VERSION ""

NS_ :

BS_:

BU_: ACU AMP CGW CLU CTM ESC FCA LDW_LKA MDPS RVM TPMS

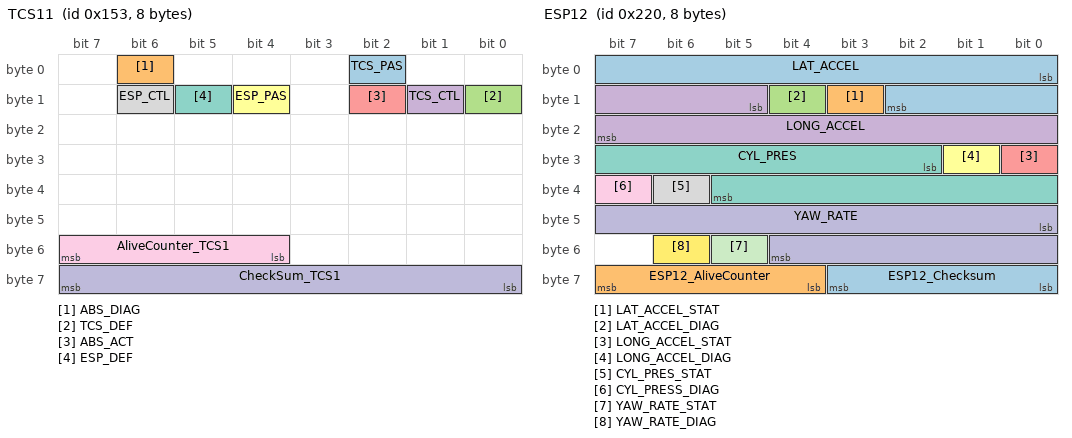
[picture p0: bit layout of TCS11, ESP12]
BO_ 339 TCS11: 8 ESC
 SG_ TCS_PAS : 2|1@1+ (1,0) [0|1] ""  FCA,LDW_LKA
 SG_ ABS_DIAG : 6|1@1+ (1,0) [0|1] ""  FCA,LDW_LKA,MDPS
 SG_ TCS_DEF : 8|1@1+ (1,0) [0|1] ""  FCA,LDW_LKA
 SG_ TCS_CTL : 9|1@1+ (1,0) [0|1] ""  FCA,LDW_LKA,MDPS
 SG_ ABS_ACT : 10|1@1+ (1,0) [0|1] ""  FCA,LDW_LKA
 SG_ ESP_PAS : 12|1@1+ (1,0) [0|1] ""  FCA,LDW_LKA
 SG_ ESP_DEF : 13|1@1+ (1,0) [0|1] ""  FCA,LDW_LKA
 SG_ ESP_CTL : 14|1@1+ (1,0) [0|1] ""  FCA,LDW_LKA,MDPS
 SG_ AliveCounter_TCS1 : 52|4@1+ (1,0) [0|14] ""  FCA
 SG_ CheckSum_TCS1 : 56|8@1+ (1,0) [0|255] ""  FCA

BO_ 356 VSM11_FS: 4 ESC
 SG_ CF_Esc_Act : 12|1@1+ (1,0) [0|1] ""  LDW_LKA,MDPS
 SG_ CRC : 24|8@1+ (1,0) [0|0] ""  LDW_LKA,MDPS

BO_ 544 ESP12: 8 ESC
 SG_ LAT_ACCEL : 0|11@1+ (0.01,-10.23) [-10.23|10.24] "m/s^2"  CLU,FCA,LDW_LKA,MDPS
 SG_ LAT_ACCEL_STAT : 11|1@1+ (1,0) [0|1] ""  CLU,FCA,LDW_LKA,MDPS
 SG_ LAT_ACCEL_DIAG : 12|1@1+ (1,0) [0|1] ""  FCA,LDW_LKA
 SG_ LONG_ACCEL : 13|11@1+ (0.01,-10.23) [-10.23|10.24] "m/s^2"  CLU,FCA,LDW_LKA
 SG_ LONG_ACCEL_STAT : 24|1@1+ (1,0) [0|1] ""  CLU,FCA,LDW_LKA
 SG_ LONG_ACCEL_DIAG : 25|1@1+ (1,0) [0|1] ""  FCA,LDW_LKA
 SG_ CYL_PRES : 26|12@1+ (0.1,0) [0|409.5] "Bar"  FCA,LDW_LKA
 SG_ CYL_PRES_STAT : 38|1@1+ (1,0) [0|1] ""  CGW,FCA,LDW_LKA
 SG_ CYL_PRESS_DIAG : 39|1@1+ (1,0) [0|1] ""  FCA,LDW_LKA
 SG_ YAW_RATE : 40|13@1+ (0.01,-40.95) [-40.95|40.96] "˚/s"  FCA,LDW_LKA,MDPS
 SG_ YAW_RATE_STAT : 53|1@1+ (1,0) [0|1] ""  FCA,LDW_LKA,MDPS
 SG_ YAW_RATE_DIAG : 54|1@1+ (1,0) [0|1] ""  FCA,LDW_LKA
 SG_ ESP12_Checksum : 56|4@1+ (1,0) [0|15] ""  FCA,LDW_LKA
 SG_ ESP12_AliveCounter : 60|4@1+ (1,0) [0|15] ""  FCA,LDW_LKA

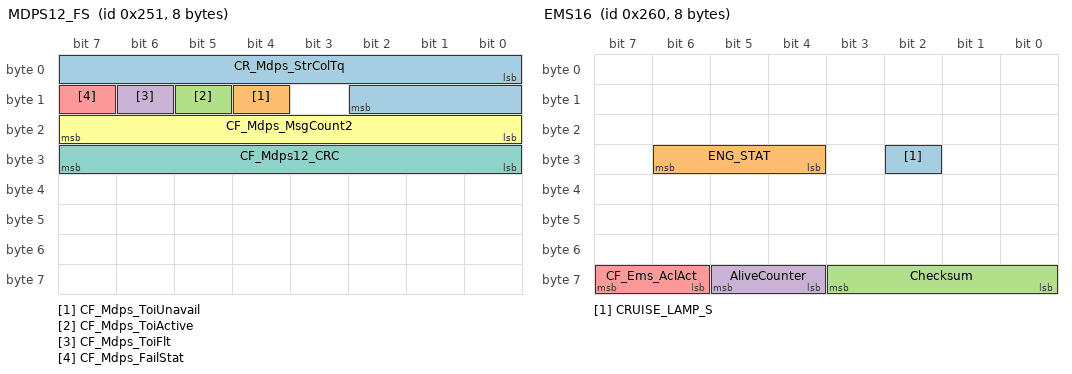
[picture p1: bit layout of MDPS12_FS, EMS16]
BO_ 593 MDPS12_FS: 8 MDPS
 SG_ CR_Mdps_StrColTq : 0|11@1+ (0.0078125,-8) [-8|7.984375] "Nm"  CGW,LDW_LKA
 SG_ CF_Mdps_ToiUnavail : 12|1@1+ (1,0) [0|1] ""  LDW_LKA
 SG_ CF_Mdps_ToiActive : 13|1@1+ (1,0) [0|1] ""  LDW_LKA
 SG_ CF_Mdps_ToiFlt : 14|1@1+ (1,0) [0|1] ""  LDW_LKA
 SG_ CF_Mdps_FailStat : 15|1@1+ (1,0) [0|1] ""  LDW_LKA
 SG_ CF_Mdps_MsgCount2 : 16|8@1+ (1,0) [0|255] ""  ESC,LDW_LKA
 SG_ CF_Mdps12_CRC : 24|8@1+ (1,0) [0|0] ""  CGW,ESC,LDW_LKA

BO_ 608 EMS16: 8 CGW
 SG_ CRUISE_LAMP_S : 26|1@1+ (1,0) [0|1] ""  CLU,LDW_LKA
 SG_ ENG_STAT : 28|3@1+ (1,0) [0|7] ""  CLU,CTM,FCA,LDW_LKA,MDPS,RVM
 SG_ Checksum : 56|4@1+ (1,0) [0|15] ""  FCA,MDPS
 SG_ AliveCounter : 60|2@1+ (1,0) [0|3] ""  FCA,MDPS
 SG_ CF_Ems_AclAct : 62|2@1+ (1,0) [0|3] ""  FCA

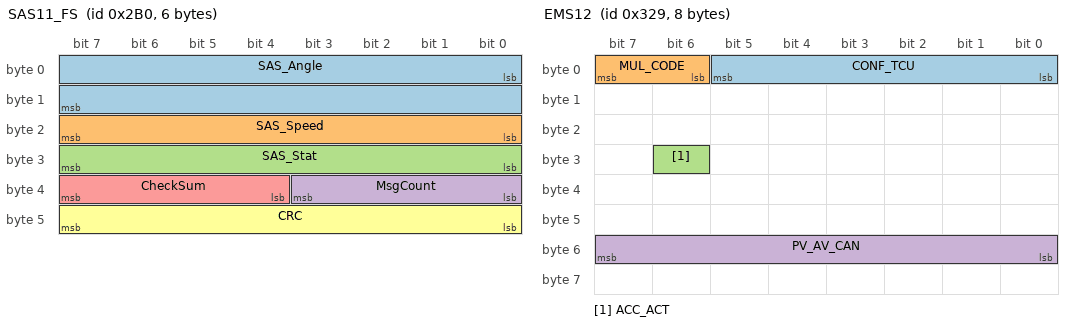
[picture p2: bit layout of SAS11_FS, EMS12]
BO_ 688 SAS11_FS: 6 MDPS
 SG_ SAS_Angle : 0|16@1- (0.1,0) [-3276.8|3276.7] "Deg"  CGW,CLU,ESC,FCA,LDW_LKA,RVM
 SG_ SAS_Speed : 16|8@1+ (4,0) [0|1016] ""  CGW,ESC,FCA,LDW_LKA
 SG_ SAS_Stat : 24|8@1+ (1,0) [0|255] ""  CGW,ESC,FCA,LDW_LKA
 SG_ MsgCount : 32|4@1+ (1,0) [0|15] ""  CGW,ESC,FCA,LDW_LKA
 SG_ CheckSum : 36|4@1+ (1,0) [0|15] ""  CGW,ESC,FCA,LDW_LKA
 SG_ CRC : 40|8@1+ (1,0) [0|0] ""  ESC,FCA,LDW_LKA

BO_ 809 EMS12: 8 CGW
 SG_ CONF_TCU : 0|6@1+ (1,0) [0|63] ""  CLU,FCA,LDW_LKA
 SG_ MUL_CODE : 6|2@1+ (1,0) [0|3] ""  CLU,FCA,LDW_LKA
 SG_ ACC_ACT : 30|1@1+ (1,0) [0|1] ""  AMP,FCA
 SG_ PV_AV_CAN : 48|8@1+ (0.3906,0) [0|99.603] "%"  FCA,LDW_LKA,MDPS

BO_ 832 LKA11_FS: 8 LDW_LKA
 SG_ CF_LKA_LaneRecogState : 0|2@1+ (1,0) [0|3] ""  CGW,CLU
 SG_ CF_LKA_SysWarning : 6|4@1+ (1,0) [0|15] ""  CLU
 SG_ CF_LKA_LHWarning : 10|2@1+ (1,0) [0|3] ""  CLU
 SG_ CF_LKA_RHWarning : 12|2@1+ (1,0) [0|3] ""  CLU
 SG_ CF_HBA_Lamp : 14|1@1+ (1,0) [0|1] ""  CLU
 SG_ CF_LKA_HandsOff_Snd : 15|1@1+ (1,0) [0|1] ""  CLU
 SG_ CR_LKA_StrToqReq : 16|11@1+ (0.0078125,-8) [-8|8] "Nm"  MDPS
 SG_ CF_LKA_ActToi : 27|1@1+ (1,0) [0|1] ""  MDPS
 SG_ CF_LKA_ToiFlt : 28|1@1+ (1,0) [0|1] ""  MDPS
 SG_ CF_HBA_SysState : 29|3@1+ (1,0) [0|7] ""  CGW,CLU
 SG_ CF_HBA_Opt_USM : 32|2@1+ (1,0) [0|3] ""  CGW,CLU
 SG_ CF_HBA_Opt : 34|1@1+ (1,0) [0|1] ""  CGW,CLU
 SG_ CF_LKA_MsgCount : 36|4@1+ (1,0) [0|15] ""  CLU,MDPS
 SG_ CF_LKA_FusionState : 45|2@1+ (1,0) [0|3] ""  Vector__XXX
 SG_ CF_LKA_CRC : 48|8@1+ (1,0) [0|255] ""  MDPS
 SG_ CF_LKA_SymbolState : 56|3@1+ (1,0) [0|7] ""  CLU
 SG_ CF_HBA_Lamp_New : 62|2@1+ (1,0) [0|1] ""  CLU

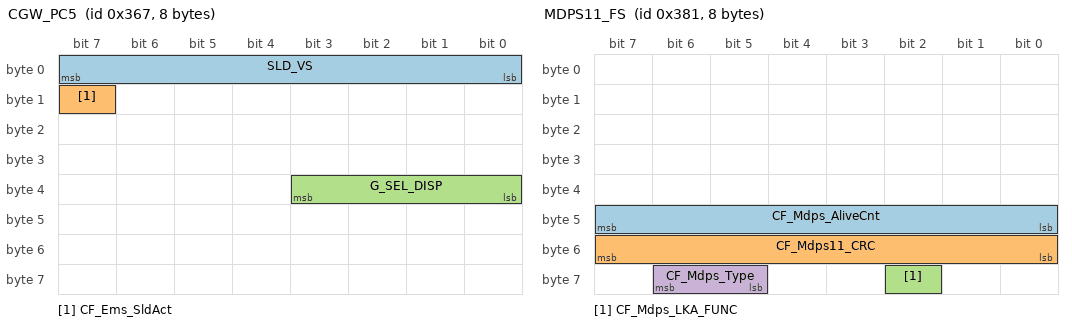
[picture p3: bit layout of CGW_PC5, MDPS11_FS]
BO_ 871 CGW_PC5: 8 CGW
 SG_ SLD_VS : 0|8@1+ (1,0) [0|255] "km/h"  CLU,LDW_LKA
 SG_ CF_Ems_SldAct : 15|1@1+ (1,0) [0|1] ""  CLU,LDW_LKA
 SG_ G_SEL_DISP : 32|4@1+ (1,0) [0|15] ""  CLU,FCA,LDW_LKA,MDPS,RVM

BO_ 897 MDPS11_FS: 8 MDPS
 SG_ CF_Mdps_AliveCnt : 40|8@1+ (1,0) [0|255] ""  LDW_LKA
 SG_ CF_Mdps11_CRC : 48|8@1+ (1,0) [0|0] ""  CGW,LDW_LKA
 SG_ CF_Mdps_LKA_FUNC : 58|1@1+ (1,0) [0|1] "flag"  LDW_LKA
 SG_ CF_Mdps_Type : 61|2@1+ (1,0) [0|2] ""  ESC,LDW_LKA

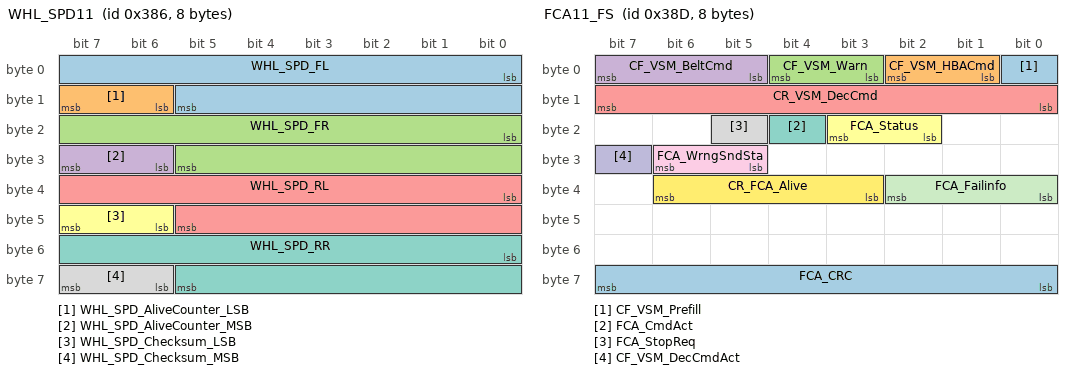
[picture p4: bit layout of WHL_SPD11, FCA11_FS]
BO_ 902 WHL_SPD11: 8 CGW
 SG_ WHL_SPD_FL : 0|14@1+ (0.03125,0) [0|511.96875] "km/h"  CLU,FCA,LDW_LKA,MDPS,RVM
 SG_ WHL_SPD_AliveCounter_LSB : 14|2@1+ (1,0) [0|3] ""  FCA,LDW_LKA
 SG_ WHL_SPD_FR : 16|14@1+ (0.03125,0) [0|511.96875] "km/h"  CLU,FCA,LDW_LKA,MDPS,RVM
 SG_ WHL_SPD_AliveCounter_MSB : 30|2@1+ (1,0) [0|3] ""  FCA,LDW_LKA
 SG_ WHL_SPD_RL : 32|14@1+ (0.03125,0) [0|511.96875] "km/h"  CLU,FCA,LDW_LKA,MDPS,RVM
 SG_ WHL_SPD_Checksum_LSB : 46|2@1+ (1,0) [0|3] ""  FCA,LDW_LKA
 SG_ WHL_SPD_RR : 48|14@1+ (0.03125,0) [0|511.96875] "km/h"  CLU,FCA,LDW_LKA,MDPS,RVM
 SG_ WHL_SPD_Checksum_MSB : 62|2@1+ (1,0) [0|3] ""  FCA,LDW_LKA

BO_ 909 FCA11_FS: 8 FCA
 SG_ CF_VSM_Prefill : 0|1@1+ (1,0) [0|1] ""  ESC
 SG_ CF_VSM_HBACmd : 1|2@1+ (1,0) [0|3] ""  ESC
 SG_ CF_VSM_Warn : 3|2@1+ (1,0) [0|3] ""  ACU,CGW,CLU,ESC
 SG_ CF_VSM_BeltCmd : 5|3@1+ (1,0) [0|7] ""  Vector__XXX
 SG_ CR_VSM_DecCmd : 8|8@1+ (0.01,0) [0|2.55] "g"  ESC
 SG_ FCA_Status : 18|2@1+ (1,0) [0|3] ""  ACU,CLU,ESC
 SG_ FCA_CmdAct : 20|1@1+ (1,0) [0|1] ""  ESC
 SG_ FCA_StopReq : 21|1@1+ (1,0) [0|1] ""  CLU,ESC
 SG_ FCA_WrngSndSta : 29|2@1+ (1,0) [0|3] ""  CLU
 SG_ CF_VSM_DecCmdAct : 31|1@1+ (1,0) [0|1] ""  ESC
 SG_ FCA_Failinfo : 32|3@1+ (1,0) [0|7] ""  ACU,CLU,ESC
 SG_ CR_FCA_Alive : 35|4@1+ (1,0) [0|15] ""  ESC
 SG_ FCA_CRC : 56|8@1+ (1,0) [0|0] ""  ESC

BO_ 913 CLU21: 8 CLU
 SG_ CF_Clu_LFASwState : 4|1@1+ (1,0) [0|1] ""  LDW_LKA

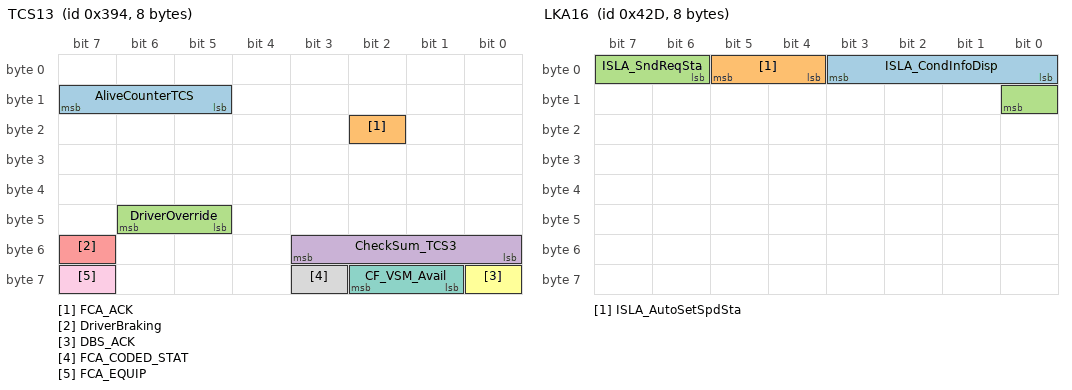
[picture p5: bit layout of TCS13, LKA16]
BO_ 916 TCS13: 8 ESC
 SG_ AliveCounterTCS : 13|3@1+ (1,0) [0|7] ""  CGW,FCA
 SG_ FCA_ACK : 18|1@1+ (1,0) [0|1] ""  FCA
 SG_ DriverOverride : 45|2@1+ (1,0) [0|3] ""  CGW,FCA,LDW_LKA
 SG_ CheckSum_TCS3 : 48|4@1+ (1,0) [0|15] ""  CGW,FCA
 SG_ DriverBraking : 55|1@1+ (1,0) [0|1] ""  CGW,FCA,LDW_LKA
 SG_ DBS_ACK : 56|1@1+ (1,0) [0|1] ""  FCA
 SG_ CF_VSM_Avail : 57|2@1+ (1,0) [0|3] ""  CGW,FCA,LDW_LKA
 SG_ FCA_CODED_STAT : 59|1@1+ (1,0) [0|0] ""  FCA
 SG_ FCA_EQUIP : 63|1@1+ (1,0) [0|1] ""  FCA

BO_ 1069 LKA16: 8 LDW_LKA
 SG_ ISLA_CondInfoDisp : 0|4@1+ (1,0) [0|0] ""  CGW,CLU
 SG_ ISLA_AutoSetSpdSta : 4|2@1+ (1,0) [0|0] ""  CLU
 SG_ ISLA_SndReqSta : 6|3@1+ (1,0) [0|0] ""  CLU

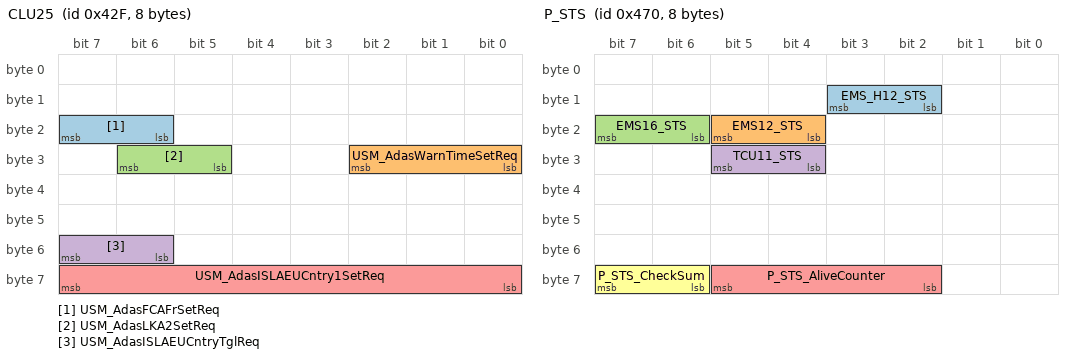
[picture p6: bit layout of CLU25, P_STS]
BO_ 1071 CLU25: 8 CLU
 SG_ USM_AdasFCAFrSetReq : 22|2@1+ (1,0) [0|3] ""  FCA
 SG_ USM_AdasWarnTimeSetReq : 24|3@1+ (1,0) [0|7] ""  FCA,LDW_LKA
 SG_ USM_AdasLKA2SetReq : 29|2@1+ (1,0) [0|3] ""  LDW_LKA
 SG_ USM_AdasISLAEUCntryTglReq : 54|2@1+ (1,0) [0|0] ""  LDW_LKA
 SG_ USM_AdasISLAEUCntry1SetReq : 56|8@1+ (1,0) [0|0] ""  LDW_LKA

BO_ 1107 CGW_PC1: 5 CGW
 SG_ ENG_SldSwSta : 28|2@1+ (1,0) [0|0] ""  CLU,LDW_LKA

BO_ 1136 P_STS: 8 CGW
 SG_ EMS_H12_STS : 10|2@1+ (1,0) [0|3] ""  FCA,LDW_LKA,MDPS
 SG_ EMS12_STS : 20|2@1+ (1,0) [0|3] ""  FCA,LDW_LKA
 SG_ EMS16_STS : 22|2@1+ (1,0) [0|3] ""  FCA,LDW_LKA,MDPS
 SG_ TCU11_STS : 28|2@1+ (1,0) [0|3] ""  FCA,LDW_LKA
 SG_ P_STS_AliveCounter : 58|4@1+ (1,0) [0|15] ""  FCA,LDW_LKA,MDPS
 SG_ P_STS_CheckSum : 62|2@1+ (1,0) [0|3] ""  FCA,LDW_LKA,MDPS

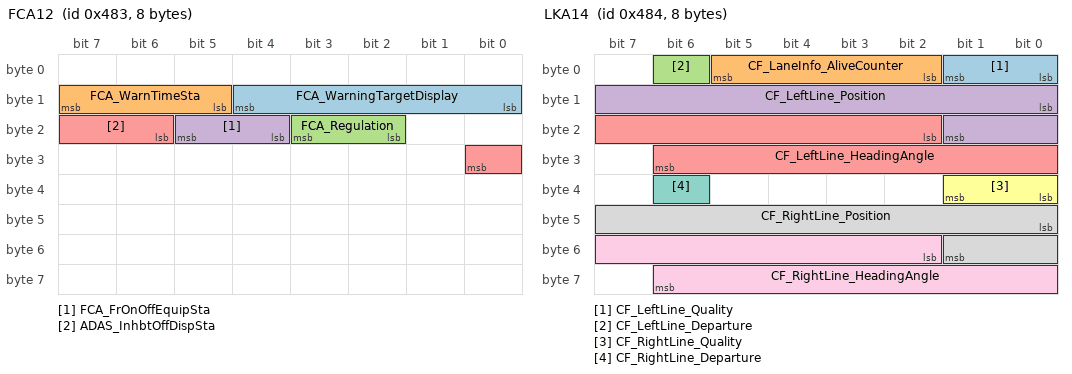
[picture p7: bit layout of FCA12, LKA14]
BO_ 1155 FCA12: 8 FCA
 SG_ FCA_WarningTargetDisplay : 8|5@1+ (1,0) [0|31] ""  CLU
 SG_ FCA_WarnTimeSta : 13|3@1+ (1,0) [0|0] ""  CGW,CLU
 SG_ FCA_Regulation : 18|2@1+ (1,0) [0|0] ""  CLU
 SG_ FCA_FrOnOffEquipSta : 20|2@1+ (1,0) [0|0] ""  CGW,CLU
 SG_ ADAS_InhbtOffDispSta : 22|3@1+ (1,0) [0|0] ""  CLU

BO_ 1156 LKA14: 8 LDW_LKA
 SG_ CF_LeftLine_Quality : 0|2@1+ (1,0) [0|0] ""  Vector__XXX
 SG_ CF_LaneInfo_AliveCounter : 2|4@1+ (1,0) [0|15] ""  Vector__XXX
 SG_ CF_LeftLine_Departure : 6|1@1+ (1,0) [0|1] ""  Vector__XXX
 SG_ CF_LeftLine_Position : 8|10@1- (0.00390625,0) [-2|1.99] ""  Vector__XXX
 SG_ CF_LeftLine_HeadingAngle : 18|13@1+ (0.0000152588,-0.0625) [-0.06|0.06] ""  Vector__XXX
 SG_ CF_RightLine_Quality : 32|2@1+ (1,0) [0|3] ""  Vector__XXX
 SG_ CF_RightLine_Departure : 38|1@1+ (1,0) [0|1] ""  Vector__XXX
 SG_ CF_RightLine_Position : 40|10@1- (0.00390625,0) [-2|1.99] "m"  Vector__XXX
 SG_ CF_RightLine_HeadingAngle : 50|13@1+ (0.0000152588,-0.0625) [-0.06|0.06] ""  Vector__XXX

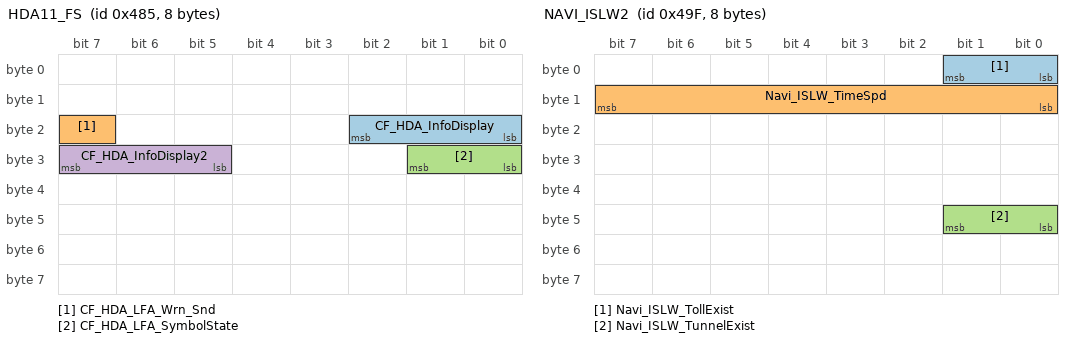
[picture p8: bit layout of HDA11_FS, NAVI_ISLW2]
BO_ 1157 HDA11_FS: 8 LDW_LKA
 SG_ CF_HDA_InfoDisplay : 16|3@1+ (1,0) [0|7] ""  CLU
 SG_ CF_HDA_LFA_Wrn_Snd : 23|1@1+ (1,0) [0|1] ""  CLU
 SG_ CF_HDA_LFA_SymbolState : 24|2@1+ (1,0) [0|3] ""  CGW,CLU
 SG_ CF_HDA_InfoDisplay2 : 29|3@1+ (1,0) [0|7] ""  CLU

BO_ 1183 NAVI_ISLW2: 8 CGW
 SG_ Navi_ISLW_TollExist : 0|2@1+ (1,0) [0|3] ""  LDW_LKA
 SG_ Navi_ISLW_TimeSpd : 8|8@1+ (1,0) [0|254] ""  LDW_LKA
 SG_ Navi_ISLW_TunnelExist : 40|2@1+ (1,0) [0|3] ""  LDW_LKA

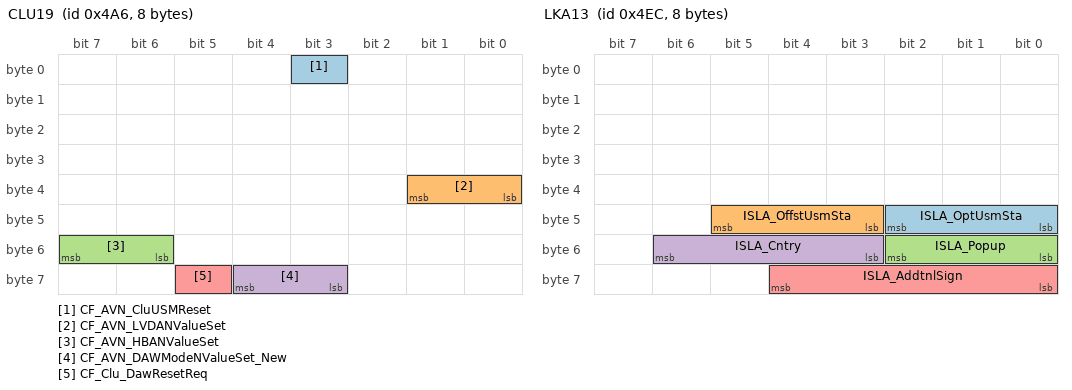
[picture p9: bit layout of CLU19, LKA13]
BO_ 1190 CLU19: 8 CLU
 SG_ CF_AVN_CluUSMReset : 3|1@1+ (1,0) [0|1] ""  FCA,LDW_LKA,RVM
 SG_ CF_AVN_LVDANValueSet : 32|2@1+ (1,0) [0|3] ""  LDW_LKA
 SG_ CF_AVN_HBANValueSet : 54|2@1+ (1,0) [0|3] ""  LDW_LKA
 SG_ CF_AVN_DAWModeNValueSet_New : 59|2@1+ (1,0) [0|3] ""  LDW_LKA
 SG_ CF_Clu_DawResetReq : 61|1@1+ (1,0) [0|1] ""  LDW_LKA

BO_ 1191 LKA15: 2 LDW_LKA
 SG_ CF_FCA_Equip_MFC : 0|3@1+ (1,0) [0|7] ""  ESC,FCA

BO_ 1193 CGW8: 8 CGW
 SG_ C_SMKTeleEngineRunning : 3|1@1+ (1,0) [0|1] ""  LDW_LKA

BO_ 1260 LKA13: 8 LDW_LKA
 SG_ ISLA_OptUsmSta : 40|3@1+ (1,0) [0|0] ""  CGW,CLU
 SG_ ISLA_OffstUsmSta : 43|3@1+ (1,0) [0|0] ""  CGW,CLU
 SG_ ISLA_Popup : 48|3@1+ (1,0) [0|0] ""  CGW,CLU
 SG_ ISLA_Cntry : 51|4@1+ (1,0) [0|0] ""  CGW,CLU
 SG_ ISLA_AddtnlSign : 56|5@1+ (1,0) [0|0] ""  CGW,CLU

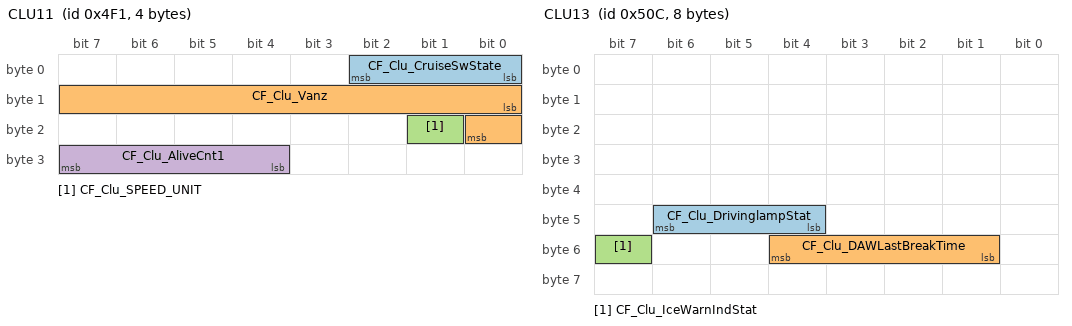
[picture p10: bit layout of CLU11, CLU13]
BO_ 1265 CLU11: 4 CLU
 SG_ CF_Clu_CruiseSwState : 0|3@1+ (1,0) [0|7] ""  CGW,LDW_LKA
 SG_ CF_Clu_Vanz : 8|9@1+ (0.5,0) [0|255.5] "km/h or MPH"  CGW,FCA,LDW_LKA,MDPS,RVM
 SG_ CF_Clu_SPEED_UNIT : 17|1@1+ (1,0) [0|1] ""  ACU,CGW,FCA,LDW_LKA,MDPS,RVM
 SG_ CF_Clu_AliveCnt1 : 28|4@1+ (1,0) [0|15] ""  CGW,FCA,LDW_LKA

BO_ 1292 CLU13: 8 CLU
 SG_ CF_Clu_DrivinglampStat : 44|3@1+ (1,0) [0|7] ""  CGW,ESC,LDW_LKA
 SG_ CF_Clu_DAWLastBreakTime : 49|4@1+ (1,0) [0|15] ""  CGW,LDW_LKA
 SG_ CF_Clu_IceWarnIndStat : 55|1@1+ (1,0) [0|1] ""  LDW_LKA

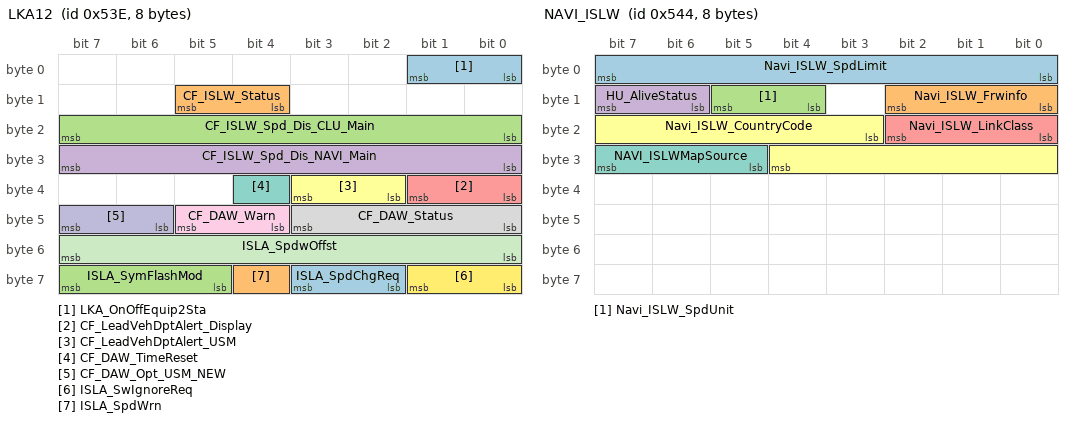
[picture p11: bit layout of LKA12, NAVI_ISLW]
BO_ 1342 LKA12: 8 LDW_LKA
 SG_ LKA_OnOffEquip2Sta : 0|2@1+ (1,0) [0|3] ""  CGW,CLU
 SG_ CF_ISLW_Status : 12|2@1+ (1,0) [0|3] ""  CLU
 SG_ CF_ISLW_Spd_Dis_CLU_Main : 16|8@1+ (1,0) [0|255] ""  CLU
 SG_ CF_ISLW_Spd_Dis_NAVI_Main : 24|8@1+ (1,0) [0|255] ""  CLU
 SG_ CF_LeadVehDptAlert_Display : 32|2@1+ (1,0) [0|3] ""  CLU
 SG_ CF_LeadVehDptAlert_USM : 34|2@1+ (1,0) [0|3] ""  CGW,CLU
 SG_ CF_DAW_TimeReset : 36|1@1+ (1,0) [0|1] ""  CLU
 SG_ CF_DAW_Status : 40|4@1+ (1,0) [0|15] ""  CLU
 SG_ CF_DAW_Warn : 44|2@1+ (1,0) [0|3] ""  CGW,CLU
 SG_ CF_DAW_Opt_USM_NEW : 46|2@1+ (1,0) [0|3] ""  CGW,CLU
 SG_ ISLA_SpdwOffst : 48|8@1+ (1,0) [0|0] ""  CLU
 SG_ ISLA_SwIgnoreReq : 56|2@1+ (1,0) [0|0] ""  CLU
 SG_ ISLA_SpdChgReq : 58|2@1+ (1,0) [0|0] ""  CLU
 SG_ ISLA_SpdWrn : 60|1@1+ (1,0) [0|0] ""  CGW,CLU
 SG_ ISLA_SymFlashMod : 61|3@1+ (1,0) [0|0] ""  CGW,CLU

BO_ 1345 CGW1: 8 CGW
 SG_ CF_Gway_DrvDrSw : 8|2@1+ (1,0) [0|3] ""  CLU,FCA,LDW_LKA
 SG_ CF_Gway_DrvSeatBeltSw : 10|2@1+ (1,0) [0|3] ""  LDW_LKA
 SG_ CF_Gway_TurnSigLh : 19|2@1+ (1,0) [0|3] ""  CLU,CTM,FCA,LDW_LKA
 SG_ CF_Gway_WiperIntT : 21|3@1+ (1,0) [0|7] ""  CLU,LDW_LKA
 SG_ CF_Gway_WiperIntSw : 24|1@1+ (1,0) [0|1] ""  LDW_LKA
 SG_ CF_Gway_WiperLowSw : 25|1@1+ (1,0) [0|1] ""  LDW_LKA
 SG_ CF_Gway_WiperHighSw : 26|1@1+ (1,0) [0|1] ""  LDW_LKA
 SG_ CF_Gway_WiperAutoSw : 27|1@1+ (1,0) [0|1] ""  LDW_LKA
 SG_ CF_Gway_RainSnsState : 28|3@1+ (1,0) [0|7] ""  LDW_LKA
 SG_ CF_Gway_HeadLampHigh : 32|1@1+ (1,0) [0|1] ""  CLU,LDW_LKA
 SG_ CF_Gway_HazardSw : 33|2@1+ (1,0) [0|3] ""  LDW_LKA
 SG_ CF_Gway_AstDrSw : 35|1@1+ (1,0) [0|1] ""  CLU,LDW_LKA
 SG_ CF_Gway_TSigRHSw : 41|1@1+ (1,0) [0|1] ""  LDW_LKA
 SG_ CF_Gway_TSigLHSw : 42|1@1+ (1,0) [0|1] ""  LDW_LKA
 SG_ CF_Gway_HBAControlMode : 52|1@1+ (1,0) [0|1] ""  LDW_LKA
 SG_ CF_Gway_InhibitRMT : 54|2@1+ (1,0) [0|3] ""  CLU,FCA,LDW_LKA,RVM
 SG_ CF_Gway_TurnSigRh : 62|2@1+ (1,0) [0|3] ""  CLU,CTM,FCA,LDW_LKA

BO_ 1348 NAVI_ISLW: 8 CGW
 SG_ Navi_ISLW_SpdLimit : 0|8@1+ (1,0) [1|254] ""  LDW_LKA
 SG_ Navi_ISLW_Frwinfo : 8|3@1+ (1,0) [0|7] ""  LDW_LKA
 SG_ Navi_ISLW_SpdUnit : 12|2@1+ (1,0) [0|3] ""  LDW_LKA
 SG_ HU_AliveStatus : 14|2@1+ (1,0) [0|3] ""  LDW_LKA
 SG_ Navi_ISLW_LinkClass : 16|3@1+ (1,0) [0|7] ""  LDW_LKA
 SG_ Navi_ISLW_CountryCode : 19|10@1+ (1,0) [0|1023] ""  LDW_LKA
 SG_ NAVI_ISLWMapSource : 29|3@1+ (1,0) [0|7] ""  LDW_LKA

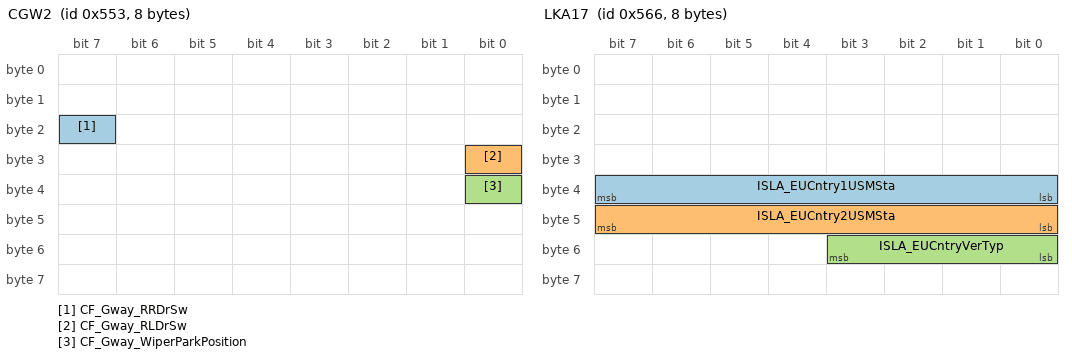
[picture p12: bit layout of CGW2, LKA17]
BO_ 1363 CGW2: 8 CGW
 SG_ CF_Gway_RRDrSw : 23|1@1+ (1,0) [0|1] ""  CLU,LDW_LKA
 SG_ CF_Gway_RLDrSw : 24|1@1+ (1,0) [0|1] ""  CLU,LDW_LKA
 SG_ CF_Gway_WiperParkPosition : 32|1@1+ (1,0) [0|1] ""  LDW_LKA

BO_ 1382 LKA17: 8 LDW_LKA
 SG_ ISLA_EUCntry1USMSta : 32|8@1+ (1,0) [0|0] ""  CGW,CLU
 SG_ ISLA_EUCntry2USMSta : 40|8@1+ (1,0) [0|0] ""  CGW,CLU
 SG_ ISLA_EUCntryVerTyp : 48|4@1+ (1,0) [0|0] ""  CGW,CLU

BO_ 1407 HU_MON_PE_01: 8 CGW
 SG_ HU_Type : 0|8@1+ (1,0) [0|255] ""  LDW_LKA,RVM
 SG_ HU_OptionInfo : 40|16@1+ (1,0) [0|0] ""  FCA

BO_ 1456 CLU12: 4 CLU
 SG_ CF_Clu_Odometer : 0|24@1+ (0.1,0) [0|1677721.4] "km"  CGW,FCA,TPMS

BO_ 1470 HU_CLU_PE_05: 8 CGW
 SG_ HU_NaviStatus : 2|2@1+ (1,0) [0|3] ""  LDW_LKA

BO_ 1474 CLU22: 8 CLU
 SG_ CF_Clu_AdasISLASetReq : 22|3@1+ (1,0) [0|0] ""  LDW_LKA
 SG_ CF_Clu_ISLAOffsetSetReq : 27|3@1+ (1,0) [0|0] ""  LDW_LKA

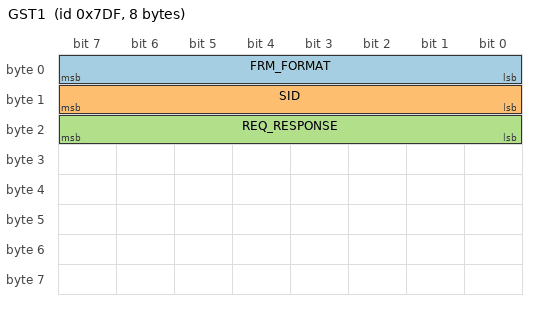
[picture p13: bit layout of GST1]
BO_ 2015 GST1: 8 CGW
 SG_ FRM_FORMAT : 0|8@1+ (1,0) [0|31] ""  CTM,LDW_LKA,MDPS
 SG_ SID : 8|8@1+ (1,0) [0|255] ""  CTM,LDW_LKA,MDPS
 SG_ REQ_RESPONSE : 16|8@1+ (1,0) [0|2] ""  CTM,LDW_LKA,MDPS

CM_ BO_ 339 "[P] Periodic";
CM_ BO_ 356 "[P] Periodic";
CM_ BO_ 544 "[P] Periodic";
CM_ BO_ 593 "[P] Periodic";
CM_ BO_ 608 "[P] Periodic";
CM_ BO_ 688 "[P] Periodic";
CM_ BO_ 809 "[P] Periodic";
CM_ BO_ 832 "[P] Periodic";
CM_ BO_ 871 "[P] Periodic";
CM_ BO_ 897 "[P] Periodic";
CM_ BO_ 902 "[P] Periodic";
CM_ BO_ 909 "[P] Periodic";
CM_ BO_ 913 "[P] Periodic";
CM_ BO_ 916 "[P] Periodic";
CM_ BO_ 1069 "[P] Periodic";
CM_ BO_ 1071 "[E] On Event";
CM_ BO_ 1107 "[P] Periodic";
CM_ BO_ 1136 "[P] Periodic";
CM_ BO_ 1155 "[PE] Periodic and On Event";
CM_ BO_ 1156 "[P] Periodic";
CM_ BO_ 1157 "[P] Periodic";
CM_ BO_ 1183 "[PE] Periodic and On Event";
CM_ BO_ 1190 "[E] On Event";
CM_ BO_ 1191 "[P] Periodic";
CM_ BO_ 1193 "[PE] Periodic and On Event";
CM_ BO_ 1260 "[P] Periodic";
CM_ BO_ 1265 "[P] Periodic";
CM_ BO_ 1292 "[P] Periodic";
CM_ BO_ 1342 "[P] Periodic";
CM_ BO_ 1345 "[PE] Periodic and On Event";
CM_ BO_ 1348 "[PE] Periodic and On Event";
CM_ BO_ 1363 "[PE] Periodic and On Event";
CM_ BO_ 1382 "[P] Periodic";
CM_ BO_ 1407 "[PE] Periodic and On Event";
CM_ BO_ 1456 "[P] Periodic";
CM_ BO_ 1470 "[PE] Periodic and On Event";
CM_ BO_ 1474 "[E] On Event";
CM_ BO_ 2015 "[E] On Event";
BA_DEF_  "BusType" STRING ;
BA_DEF_  "DBName" STRING ;
BA_DEF_  "Baudrate" INT 50000 1000000;
BA_DEF_  "Datarate" INT 2000000 8000000;
BA_DEF_  "BRS" INT 0 1;
BA_DEF_ BO_  "GenMsgCycleTime" INT 0 2000;
BA_DEF_ BO_  "GenMsgSendType" ENUM  "Cyclic","NoMsgSendType";
BA_DEF_ BO_  "VFrameFormat" ENUM  "StandardCAN","ExtendedCAN","reserved","J1939PG","reserved","reserved","reserved","reserved","reserved","reserved","reserved","reserved","reserved","reserved","StandardCAN_FD","ExtendedCAN_FD";
BA_DEF_ SG_  "UserSigValidity" ENUM  "B+","ACC","IG","IG1","IG2","IG3","IG1 or IG2","IG1 or IG3","Undef";
BA_DEF_ SG_  "GenSigStartValue" FLOAT -2147483647 4294967295;
BA_DEF_DEF_  "BusType" "CAN FD";
BA_DEF_DEF_  "DBName" "MANDO_ADAS";
BA_DEF_DEF_  "Baudrate" 500000;
BA_DEF_DEF_  "Datarate" 2000000;
BA_DEF_DEF_  "BRS" 1;
BA_DEF_DEF_  "GenMsgCycleTime" 200;
BA_DEF_DEF_  "GenMsgSendType" "Cyclic";
BA_DEF_DEF_  "VFrameFormat" "StandardCAN_FD";
BA_DEF_DEF_  "UserSigValidity" "IG1";
BA_DEF_DEF_  "GenSigStartValue" 0;
BA_ "GenMsgCycleTime" BO_ 339 10;
BA_ "VFrameFormat" BO_ 339 0;
BA_ "GenMsgCycleTime" BO_ 356 10;
BA_ "VFrameFormat" BO_ 356 0;
BA_ "GenMsgCycleTime" BO_ 544 10;
BA_ "VFrameFormat" BO_ 544 0;
BA_ "GenMsgCycleTime" BO_ 593 10;
BA_ "VFrameFormat" BO_ 593 0;
BA_ "GenMsgCycleTime" BO_ 608 10;
BA_ "VFrameFormat" BO_ 608 0;
BA_ "GenMsgCycleTime" BO_ 688 10;
BA_ "VFrameFormat" BO_ 688 0;
BA_ "GenMsgCycleTime" BO_ 809 10;
BA_ "VFrameFormat" BO_ 809 0;
BA_ "GenMsgCycleTime" BO_ 832 10;
BA_ "VFrameFormat" BO_ 832 0;
BA_ "GenMsgCycleTime" BO_ 871 10;
BA_ "VFrameFormat" BO_ 871 0;
BA_ "GenMsgCycleTime" BO_ 897 20;
BA_ "VFrameFormat" BO_ 897 0;
BA_ "GenMsgCycleTime" BO_ 902 20;
BA_ "VFrameFormat" BO_ 902 0;
BA_ "GenMsgCycleTime" BO_ 909 20;
BA_ "VFrameFormat" BO_ 909 0;
BA_ "GenMsgCycleTime" BO_ 913 20;
BA_ "VFrameFormat" BO_ 913 0;
BA_ "GenMsgCycleTime" BO_ 916 20;
BA_ "VFrameFormat" BO_ 916 0;
BA_ "GenMsgCycleTime" BO_ 1069 100;
BA_ "VFrameFormat" BO_ 1069 0;
BA_ "GenMsgSendType" BO_ 1071 1;
BA_ "GenMsgCycleTime" BO_ 1071 0;
BA_ "VFrameFormat" BO_ 1071 0;
BA_ "GenMsgCycleTime" BO_ 1107 20;
BA_ "VFrameFormat" BO_ 1107 0;
BA_ "GenMsgCycleTime" BO_ 1136 20;
BA_ "VFrameFormat" BO_ 1136 0;
BA_ "GenMsgSendType" BO_ 1155 1;
BA_ "VFrameFormat" BO_ 1155 0;
BA_ "GenMsgCycleTime" BO_ 1156 70;
BA_ "VFrameFormat" BO_ 1156 0;
BA_ "GenMsgCycleTime" BO_ 1157 50;
BA_ "VFrameFormat" BO_ 1157 0;
BA_ "GenMsgSendType" BO_ 1183 1;
BA_ "VFrameFormat" BO_ 1183 0;
BA_ "GenMsgSendType" BO_ 1190 1;
BA_ "GenMsgCycleTime" BO_ 1190 0;
BA_ "VFrameFormat" BO_ 1190 0;
BA_ "GenMsgCycleTime" BO_ 1191 500;
BA_ "VFrameFormat" BO_ 1191 0;
BA_ "GenMsgSendType" BO_ 1193 1;
BA_ "VFrameFormat" BO_ 1193 0;
BA_ "GenMsgCycleTime" BO_ 1260 100;
BA_ "VFrameFormat" BO_ 1260 0;
BA_ "GenMsgCycleTime" BO_ 1265 20;
BA_ "VFrameFormat" BO_ 1265 0;
BA_ "GenMsgCycleTime" BO_ 1292 100;
BA_ "VFrameFormat" BO_ 1292 0;
BA_ "GenMsgCycleTime" BO_ 1342 100;
BA_ "VFrameFormat" BO_ 1342 0;
BA_ "GenMsgSendType" BO_ 1345 1;
BA_ "GenMsgCycleTime" BO_ 1345 100;
BA_ "VFrameFormat" BO_ 1345 0;
BA_ "GenMsgSendType" BO_ 1348 1;
BA_ "VFrameFormat" BO_ 1348 0;
BA_ "GenMsgSendType" BO_ 1363 1;
BA_ "VFrameFormat" BO_ 1363 0;
BA_ "VFrameFormat" BO_ 1382 0;
BA_ "GenMsgSendType" BO_ 1407 1;
BA_ "GenMsgCycleTime" BO_ 1407 2000;
BA_ "VFrameFormat" BO_ 1407 0;
BA_ "GenMsgCycleTime" BO_ 1456 1000;
BA_ "VFrameFormat" BO_ 1456 0;
BA_ "GenMsgSendType" BO_ 1470 1;
BA_ "GenMsgCycleTime" BO_ 1470 1000;
BA_ "VFrameFormat" BO_ 1470 0;
BA_ "GenMsgSendType" BO_ 1474 1;
BA_ "GenMsgCycleTime" BO_ 1474 0;
BA_ "VFrameFormat" BO_ 1474 0;
BA_ "GenMsgSendType" BO_ 2015 1;
BA_ "GenMsgCycleTime" BO_ 2015 0;
BA_ "VFrameFormat" BO_ 2015 0;
BA_ "GenSigStartValue" SG_ 356 CRC 255;
BA_ "GenSigStartValue" SG_ 593 CR_Mdps_StrColTq 1024;
BA_ "GenSigStartValue" SG_ 593 CF_Mdps12_CRC 255;
BA_ "GenSigStartValue" SG_ 688 SAS_Angle 32767;
BA_ "GenSigStartValue" SG_ 688 SAS_Speed 255;
BA_ "GenSigStartValue" SG_ 688 SAS_Stat 14;
BA_ "GenSigStartValue" SG_ 688 CRC 255;
BA_ "GenSigStartValue" SG_ 832 CR_LKA_StrToqReq 1024;
BA_ "GenSigStartValue" SG_ 832 CF_LKA_CRC 255;
BA_ "GenSigStartValue" SG_ 871 G_SEL_DISP 9;
BA_ "GenSigStartValue" SG_ 897 CF_Mdps11_CRC 255;
BA_ "GenSigStartValue" SG_ 909 FCA_CRC 255;
BA_ "GenSigStartValue" SG_ 1069 ISLA_CondInfoDisp 15;
BA_ "GenSigStartValue" SG_ 1136 EMS_H12_STS 1;
BA_ "GenSigStartValue" SG_ 1136 EMS12_STS 1;
BA_ "GenSigStartValue" SG_ 1136 EMS16_STS 1;
BA_ "GenSigStartValue" SG_ 1136 TCU11_STS 1;
BA_ "GenSigStartValue" SG_ 1260 ISLA_Cntry 15;
BA_ "GenSigStartValue" SG_ 1348 Navi_ISLW_SpdLimit 255;
BA_ "GenSigStartValue" SG_ 1348 Navi_ISLW_Frwinfo 7;
BA_ "GenSigStartValue" SG_ 1348 Navi_ISLW_SpdUnit 3;
BA_ "GenSigStartValue" SG_ 1348 HU_AliveStatus 3;
BA_ "GenSigStartValue" SG_ 1348 Navi_ISLW_LinkClass 7;
BA_ "GenSigStartValue" SG_ 1348 Navi_ISLW_CountryCode 1023;
BA_ "GenSigStartValue" SG_ 1348 NAVI_ISLWMapSource 7;
BA_ "GenSigStartValue" SG_ 1407 HU_Type 255;
BA_ "GenSigStartValue" SG_ 1407 HU_OptionInfo 32768;
BA_ "GenSigStartValue" SG_ 1470 HU_NaviStatus 3;
VAL_ 339 TCS_PAS 1 "TCS is disabled by user" ;
VAL_ 339 ABS_DIAG 0 "ABS/TCS/ESC is not diagnostic mode" 1 "ABS/TCS/ESC is diagnostic mode" ;
VAL_ 339 TCS_DEF 1 "TCS is defective (failed)" ;
VAL_ 339 TCS_CTL 1 "TCS Active" ;
VAL_ 339 ABS_ACT 0 "ABS control inactive" 1 "ABS control active" ;
VAL_ 339 ESP_PAS 1 "ESC disabled by user (SW off)" ;
VAL_ 339 ESP_DEF 1 "ESC is defective (failed)" ;
VAL_ 339 ESP_CTL 1 "ESC active" ;
VAL_ 356 CF_Esc_Act 0 "VSM control inactive0H" 1 "VSM control active" ;
VAL_ 544 LAT_ACCEL_STAT 0 "Lateral acceleration signal is valid" 1 "Lateral acceleration signal is invalid" ;
VAL_ 544 LAT_ACCEL_DIAG 0 "Lateral acceleration signal is available" 1 "Lateral acceleration signal is not available temporarily" ;
VAL_ 544 LONG_ACCEL_STAT 0 "Longitudinal acceleration signal is valid" 1 "Longitudinal acceleration signal is invalid" ;
VAL_ 544 LONG_ACCEL_DIAG 0 "Longitudinal acceleration signal is available" 1 "Longitudinal acceleration signal is not available temporarily" ;
VAL_ 544 CYL_PRES_STAT 0 "Master cylinder pressure signal is valid" 1 "Master cylinder pressure signal is invalid" ;
VAL_ 544 CYL_PRESS_DIAG 0 "Master cylinder pressure signal is available" 1 "Master cylinder pressure is not available temporarily" ;
VAL_ 544 YAW_RATE_STAT 0 "Yaw rate sensor signal is valid" 1 "Yaw rate sensor signal is invalid" ;
VAL_ 544 YAW_RATE_DIAG 0 "Yaw rate signal is available" 1 "Yaw rate signal is not available temporarily" ;
VAL_ 593 CF_Mdps_ToiUnavail 0 "Available" 1 "Unavailable" ;
VAL_ 593 CF_Mdps_ToiActive 0 "Deactivated" 1 "Activated" ;
VAL_ 593 CF_Mdps_ToiFlt 0 "No fault" 1 "Faulty" ;
VAL_ 593 CF_Mdps_FailStat 0 "Not in fail state" 1 "In fail state" ;
VAL_ 608 CRUISE_LAMP_S 0 "Cruise SET switch indication lamp turn OFF" 1 "Cruise SET switch indication lamp turn ON" ;
VAL_ 608 ENG_STAT 0 "Engine Stop" 1 "Cranking" 2 "Stalled" 3 "Running" 4 "Reserved" 5 "Reserved" 6 "Reserved" 7 "Fault" ;
VAL_ 608 CF_Ems_AclAct 0 "Accelerator pedal not pressed" 1 "Accelerator pedal pressed" 2 "Reserved" 3 "Accelerator pedal position sensor failure" ;
VAL_ 809 CONF_TCU 0 "A/T vehicle (Step Shift A/T)" 9 "E-CLUTCH vehicle" 10 "CVT vehicle (CVT A/T)" 11 "DCT vehicle (DCT A/T)" 14 "AMT vehicle" 15 "M/T vehicle" ;
VAL_ 809 MUL_CODE 0 "CAN_VERS" 1 "CONF_TCU" 2 "OBD_FRF_ACK" 3 "TQ_STND" ;
VAL_ 809 ACC_ACT 0 "Auto cruise control is not active" 1 "Auto cruise control is active" ;
VAL_ 809 PV_AV_CAN 0 "Accelerator Pedal not activated" 254 "Accelerator Pedal fully activated" 255 "Accelerator Pedal is defective (fail state) orNon-ETC system (APS is not installed)" ;
VAL_ 832 CF_LKA_LaneRecogState 0 "Not Recognition" 1 "Left Lane Recognition" 2 "Right Lane Recognition" 3 "Full Lane Recognition" ;
VAL_ 832 CF_LKA_SysWarning 0 "No Info" 4 "Hands-Off Warning1" 5 "Hands-Off Warning2" 6 "Hands-Off Warning3" 9 "System Automatic off" 14 "Blockage Warning" 15 "System Fail" ;
VAL_ 832 CF_LKA_LHWarning 0 "No Warning" 1 "Lane Departure Warning" 2 "Reserved" 3 "Haptic Warning & Display" ;
VAL_ 832 CF_LKA_RHWarning 0 "No Warning" 1 "Lane Departure Warning" 2 "Reserved" 3 "Haptic Warning & Display" ;
VAL_ 832 CF_HBA_Lamp 0 "HBA Indicator Lamp Off" 1 "HBA Indicator Lamp On (Green)" ;
VAL_ 832 CF_LKA_HandsOff_Snd 0 "Off" 1 "Hands-off Sound Warning" ;
VAL_ 832 CF_LKA_ActToi 0 "De-activate TOI" 1 "Activate TOI" ;
VAL_ 832 CF_LKA_ToiFlt 0 "No Fault" 1 "Fault Present" ;
VAL_ 832 CF_HBA_SysState 0 "Default (Disable)" 1 "HBA Enable & High Beam Off" 2 "HBA Enable & High Beam On" 3 "Reserved" 4 "Reserved" 5 "Reserved" 6 "Reserved" 7 "System Fail" ;
VAL_ 832 CF_HBA_Opt_USM 0 "None HBA Option (Default)" 1 "HBA Function Off" 2 "HBA Function On" 3 "Invalid (Fail)" ;
VAL_ 832 CF_HBA_Opt 0 "None HBA Option (Default)" 1 "HBA System Enable" ;
VAL_ 832 CF_LKA_FusionState 0 "Normal" 1 "Fusion Disabled" 2 "SCC Communication Error" 3 "Camera Blockage" ;
VAL_ 832 CF_LKA_SymbolState 0 "Off" 1 "White On" 2 "Green On" 3 "Green Blink" 4 "Orange On" 5 "Orange Blink" 6 "Off for Regulation (Orange On)" 7 "Temp. Unavailable (Orange On)" ;
VAL_ 832 CF_HBA_Lamp_New 0 "HBA Indicator Lamp Off" 1 "HBA Indicator Lamp On (White)" ;
VAL_ 871 CF_Ems_SldAct 0 "Speed limiter function is not active" 1 "Speed limiter function is active" ;
VAL_ 871 G_SEL_DISP 0 "P" 1 "L" 2 "2" 3 "3" 4 "DS Mode" 5 "D" 6 "N" 7 "R" 8 "sports mode / manual shift / paddle shift" 9 "Not Display at Cluster" 10 "Sub-Rom Communication" 11 "Sub-Rom Communication Error" 12 "Paddle shift (D-position)" 13 "Reserved" 14 "Intermediate Position" 15 "fault" ;
VAL_ 897 CF_Mdps_LKA_FUNC 0 "The LKA function of MDPS is not plugged in (unplugged)." 1 "The LKA function of MDPS is plugged in." ;
VAL_ 897 CF_Mdps_Type 0 "C-MDPS" 1 "R-MDPS(Dual Pinion)" 2 "R-MDPS(Belt)" 3 "Reserved" ;
VAL_ 909 CF_VSM_Prefill 0 "No pre-fill" 1 "Pre-fill" ;
VAL_ 909 CF_VSM_HBACmd 0 "Standard threshold" 1 "Lowered threshold 1" 2 "Lowered threshold 2" 3 "Lowered threshold 3" ;
VAL_ 909 CF_VSM_Warn 0 "No warning" 1 "Warning level 1" 2 "Warning level 2" 3 "Warning level 3" ;
VAL_ 909 CF_VSM_BeltCmd 0 "Release" 1 "Pre-crash full retraction" 2 "Haptic warning" ;
VAL_ 909 FCA_Status 0 "Not Applied" 1 "System Off" 2 "System On" 3 "Invaild (Fail)" ;
VAL_ 909 FCA_CmdAct 0 "No request" 1 "Request valid" ;
VAL_ 909 FCA_StopReq 0 "No request" 1 "Stop control is required" ;
VAL_ 909 FCA_WrngSndSta 0 "No warning" 1 "Warning 1" 2 "Warning 2" 3 "Warning 3" ;
VAL_ 909 CF_VSM_DecCmdAct 0 "No request" 1 "Request valid" ;
VAL_ 909 FCA_Failinfo 0 "Normal" 1 "Temp. Unavailable by Front View Camera (Sensor fusion)" 2 "Temp. Unavailable by Front Radar (Radar only or Sensor fusion in Radar)" 3 "Service Required" 4 "Temp. Unavailable by Front View Camera (Camera only)" 5 "Temp. Unavailable by Front View Camera (Sensor fusion in ADAS_DRV)" 6 "Temp. Unavailable by Front Radar (Sensor fusion in Camera)" 7 "Reserved" ;
VAL_ 909 CR_FCA_Alive 15 "Signal Invalid" ;
VAL_ 913 CF_Clu_LFASwState 0 "Off" 1 "On" ;
VAL_ 916 FCA_ACK 0 "Not valid" 1 "All FCA  function valid" ;
VAL_ 916 DriverOverride 0 "No override" 1 "Override by acceleration pedal" 2 "Override by deceleration" 3 "Not defined" ;
VAL_ 916 DriverBraking 0 "Brake pedal not pressed" 1 "Brake pedal pressed" ;
VAL_ 916 DBS_ACK 0 "DBS control inactive" 1 "DBS control active" ;
VAL_ 916 CF_VSM_Avail 0 "Available" 1 "Temporarily not Available" 2 "Permanently not Available" 3 "AEB Communication Error" ;
VAL_ 916 FCA_CODED_STAT 0 "Not Coded" 1 "Coding Completed" ;
VAL_ 916 FCA_EQUIP 0 "FCA is not equipped" 1 "FCA is equipped" ;
VAL_ 1069 ISLA_CondInfoDisp 0 "None" 1 "Rain" 2 "Snow" 3 "Snow / Rain" 4 "Trailer" 5 "Reserved" 6 "Reserved" 7 "Reserved" 8 "Reserved" 9 "Reserved" 10 "Reserved" 11 "Reserved" 12 "Reserved" 13 "Reserved" 14 "Generic" 15 "Initial Value (Default)" ;
VAL_ 1069 ISLA_AutoSetSpdSta 0 "AutoSet Speed OFF" 1 "AutoSet Speed ON" 2 "Reserved" 3 "Invalid" ;
VAL_ 1069 ISLA_SndReqSta 0 "None (Default)" 1 "Over Speed Warning" 2 "Traffic Sign Changed" 3 "Reserved" 4 "Reserved" 5 "Reserved" 6 "Reserved" 7 "Invalid" ;
VAL_ 1071 USM_AdasFCAFrSetReq 0 "Default" 1 "Off" 2 "On" 3 "Invalid" ;
VAL_ 1071 USM_AdasWarnTimeSetReq 0 "Default" 1 "Late" 2 "Normal" 3 "Reserved" 4 "Reserved" 5 "Reserved" 6 "Reserved" 7 "Invliad" ;
VAL_ 1071 USM_AdasLKA2SetReq 0 "Default" 1 "Off" 2 "On" 3 "Invalid" ;
VAL_ 1071 USM_AdasISLAEUCntryTglReq 0 "default" 1 "toggle" 2 "reserved" 3 "invalid" ;
VAL_ 1071 USM_AdasISLAEUCntry1SetReq 0 "Defualt" 1 "1~254:Country1 ~ 254" 254 "1~254:Country1 ~ 254" 255 "Invalid" ;
VAL_ 1107 ENG_SldSwSta 0 "Speed limiter function is OFF" 1 "Speed limiter function is Active(Kickdown)" 2 "Speed limiter function is Pause" 3 "Error indicator" ;
VAL_ 1136 EMS_H12_STS 0 "Normal status" 1 "Not Received" 2 "Reserved" 3 "Invalid" ;
VAL_ 1136 EMS12_STS 0 "Normal status" 1 "Not Received" 2 "Reserved" 3 "Invalid" ;
VAL_ 1136 EMS16_STS 0 "Normal status" 1 "Not Received" 2 "Reserved" 3 "Invalid" ;
VAL_ 1136 TCU11_STS 0 "Normal status" 1 "Not Received" 2 "Reserved" 3 "Invalid" ;
VAL_ 1155 FCA_WarningTargetDisplay 0 "None" 1 "FCA" 2 "Reserved" 3 "Reserved" 4 "Reserved" 5 "Reserved" 6 "Reserved" 7 "FCA-JC(L)" 8 "FCA-JC(R)" 9 "Reserved" 10 "Reserved" 11 "FCA-JT(L)" 12 "FCA-JT(R)" 13 "Reserved" 14 "Reserved" ;
VAL_ 1155 FCA_WarnTimeSta 0 "Default" 1 "Late" 2 "Normal" 3 "Reserved" 4 "Reserved" 5 "Reserved" 6 "Reserved" 7 "Invalid" ;
VAL_ 1155 FCA_Regulation 0 "No Warning" 1 "FCA Amber Warning on" 2 "FCA Red Warning blinking" 3 "Reserved" ;
VAL_ 1155 FCA_FrOnOffEquipSta 0 "Default" 1 "Off" 2 "On" 3 "Invalid" ;
VAL_ 1155 ADAS_InhbtOffDispSta 0 "Default" 1 "Inhibit Off in regulation(Cluster)" 2 "Inhibit Off in regulation(H/UNIT)" 3 "reserved" 4 "reserved" 5 "reserved" 6 "reserved" 7 "reserved" ;
VAL_ 1156 CF_LeftLine_Quality 0 "Very Low Quality" 1 "Low Quality" 2 "High Quality" 3 "Very High Quality" ;
VAL_ 1156 CF_LeftLine_Departure 0 "No Left Line Departure" 1 "Left Line Departure" ;
VAL_ 1156 CF_RightLine_Quality 0 "Very Low Quality" 1 "Low Quality" 2 "High Quality" 3 "Very High Quality" ;
VAL_ 1156 CF_RightLine_Departure 0 "No Right Line Departure" 1 "Right Line Departure" ;
VAL_ 1157 CF_HDA_InfoDisplay 0 "no pop-up" 1 "system start pop-up" 2 "system auto disengaged pop-up by highway off" 3 "system Fail pop-up(LFA)" 4 "system Fail pop-up(HDA)" 5 "Hands-off pop up" 6 "Hands-off pop up w/ sound" 7 "System Automatic off" ;
VAL_ 1157 CF_HDA_LFA_Wrn_Snd 0 "Off" 1 "Additional Warning Sound" ;
VAL_ 1157 CF_HDA_LFA_SymbolState 0 "Off" 1 "Gray" 2 "Green" 3 "White blink" ;
VAL_ 1157 CF_HDA_InfoDisplay2 0 "no pop-up" 1 "System Automatic off (LFA)" 2 "System Automatic off (HDA)" ;
VAL_ 1183 Navi_ISLW_TollExist 0 "None" 1 "Normal Toll" 2 "Elect Toll" 3 "Invalid" ;
VAL_ 1183 Navi_ISLW_TimeSpd 0 "None" 1 "1~253:1~253" 253 "1~253:1~253" 254 "Unlimited" 255 "Invalid" ;
VAL_ 1183 Navi_ISLW_TunnelExist 0 "None" 1 "Exist" 2 "Reserved" 3 "Invalid" ;
VAL_ 1190 CF_AVN_CluUSMReset 0 "Defualt" 1 "Reset" ;
VAL_ 1190 CF_AVN_LVDANValueSet 0 "Default" 1 "Off" 2 "On" 3 "Invalid" ;
VAL_ 1190 CF_AVN_HBANValueSet 0 "Default(NoneHBA)" 1 "HBA Function Off" 2 "HBA Function On" 3 "Invalid" ;
VAL_ 1190 CF_AVN_DAWModeNValueSet_New 0 "Default" 1 "Off" 2 "On" 3 "Invalid" ;
VAL_ 1190 CF_Clu_DawResetReq 0 "Default" 1 "ResetReq" ;
VAL_ 1191 CF_FCA_Equip_MFC 0 "No Coding" 1 "Sensor Fusion FCA" 2 "Camera only FCA" 3 "No FCA Option" 4 "Reserved" 5 "Reserved" 6 "Reserved" 7 "Reserved" ;
VAL_ 1193 C_SMKTeleEngineRunning 0 "Off" 1 "Tele Running" ;
VAL_ 1260 ISLA_OptUsmSta 0 "None ISLA Option (Delete ISLA Menu)" 1 "Off" 2 "Warning" 3 "Assist" 4 "Reserved" 5 "Reserved" 6 "Reserved" 7 "Invalid (GRAY)" ;
VAL_ 1260 ISLA_OffstUsmSta 0 "None Offset Function (Delete Offset Menu)" 1 "-10kph or -5mph" 2 "-5kph or -3mph" 3 "0kph or 0mph" 4 "+5kph or +3mph" 5 "+10kph or +5mph" 6 "Reserved" 7 "Invalid (GRAY)" ;
VAL_ 1260 ISLA_Popup 0 "No Popup" 1 "MSLA Speed will Change" 2 "MSLA Speed has Changed" 3 "CC_SCC Speed will Change" 4 "CC_SCC Speed has Changed" 5 "Reserved" 6 "Reserved" 7 "Reserved" ;
VAL_ 1260 ISLA_Cntry 0 "Europe/Russia" 1 "Domestic" 2 "China" 3 "USA" 4 "Canada" 5 "Australia" 6 "Reserved" 7 "Reserved" 8 "Reserved" 9 "Reserved" 10 "Reserved" 11 "Reserved" 12 "Reserved" 13 "Reserved" 14 "Reserved" 15 "Initial Value (default)" ;
VAL_ 1260 ISLA_AddtnlSign 0 "No Recognition (default)" 1 "School Crossing" 2 "Pedestrian Crossing" 3 "Bicycle Crossing" 4 "Reserved" 5 "Reserved" 6 "Reserved" 7 "Reserved" 8 "Stop" 9 "Yield" 10 "Stop Ahead" 11 "Yield Ahead" 12 "Road Construction Ahead" 13 "Lane Reduction" 14 "Reserved" 15 "Reserved" 16 "Do Not Pass (LHD)" 17 "Do Not Pass (RHD)" 18 "Reserved" 19 "Do Not Enter" 20 "Reserved" 21 "Reserved" 22 "Reserved" 23 "Reserved" 24 "Roundabout (LHD)" 25 "Roundabout (RHD)" 26 "Right Curve" 27 "Left Curve" 28 "Right and Left Curves" 29 "Left and Right Curves" 30 "Reserved" 31 "Reserved" ;
VAL_ 1265 CF_Clu_CruiseSwState 0 "Idle Position" 1 "Resume/Plus" 2 "Set/Minus" 3 "Time gap (Distance, SCC only)" 4 "ACC/SCC cancel" 7 "Reserved" ;
VAL_ 1265 CF_Clu_SPEED_UNIT 0 "km/h" 1 "MPH" ;
VAL_ 1292 CF_Clu_DrivinglampStat 0 "Reserved" 1 "Normal" 2 "Eco" 3 "Sport" 4 "Sport+" 5 "Smart" 6 "Individual" 7 "N-mode" ;
VAL_ 1292 CF_Clu_DAWLastBreakTime 0 "Value x 30min (0~6.5hr)" 1 "Value x 30min (0~6.5hr)" 2 "Value x 30min (0~6.5hr)" 3 "Value x 30min (0~6.5hr)" 4 "Value x 30min (0~6.5hr)" 5 "Value x 30min (0~6.5hr)" 6 "Value x 30min (0~6.5hr)" 7 "Value x 30min (0~6.5hr)" 8 "Value x 30min (0~6.5hr)" 9 "Value x 30min (0~6.5hr)" 10 "Value x 30min (0~6.5hr)" 11 "Value x 30min (0~6.5hr)" 12 "Value x 30min (0~6.5hr)" 13 "Value x 30min (0~6.5hr)" 14 "7hr or more" 15 "Invalid" ;
VAL_ 1292 CF_Clu_IceWarnIndStat 0 "Off" 1 "On" ;
VAL_ 1342 LKA_OnOffEquip2Sta 0 "Default" 1 "Off" 2 "On" 3 "Invalid" ;
VAL_ 1342 CF_ISLW_Status 0 "ISLW Valid (default)" 1 "ISLW Invalid/Failure" 2 "ISLW Temporary Unavailable" 3 "Off warning (Optional by country)" ;
VAL_ 1342 CF_ISLW_Spd_Dis_CLU_Main 0 "No Recognition (Default)" 1 "1~252:1~252" 252 "1~252:1~252" 253 "Unlimited Speed" 254 "Reserved" 255 "Invalid" ;
VAL_ 1342 CF_ISLW_Spd_Dis_NAVI_Main 0 "No Recognition (Default)" 1 "1~252:1~252" 252 "1~252:1~252" 253 "Unlimited Speed" 254 "Reserved" 255 "Invalid" ;
VAL_ 1342 CF_LeadVehDptAlert_Display 0 "Default" 1 "Display “Lead Vehicle Departure Alert”" 2 "Reserved" 3 "Invalid" ;
VAL_ 1342 CF_LeadVehDptAlert_USM 0 "No Option (default)" 1 "Off" 2 "On" 3 "Invalid" ;
VAL_ 1342 CF_DAW_TimeReset 0 "No Signal" 1 "Time Reset" ;
VAL_ 1342 CF_DAW_Status 0 "System OFF" 1 "Attention Level 1" 2 "Attention Level 2" 3 "Attention Level 3" 4 "Attention Level 4" 5 "Attention Level 5" 6 "Attention Level 0" 7 "Reserved" 8 "Reserved" 9 "Reserved" 10 "Reserved" 11 "Reserved" 12 "Reserved" 13 "System Blockage" 14 "System Standby" 15 "System Fail" ;
VAL_ 1342 CF_DAW_Warn 0 "No Warning" 1 "Rest Recommend Warning" 2 "Hands-Off TMS Call Request" 3 "Reserved" ;
VAL_ 1342 CF_DAW_Opt_USM_NEW 0 "None DAW Option(Default)" 1 "System OFF" 2 "System ON" 3 "Invalid" ;
VAL_ 1342 ISLA_SpdwOffst 0 "No recognition" 1 "1~252:1~252 kph or mph" 252 "1~252:1~252 kph or mph" 253 "Unlimited Speed" 254 "Reserved" 255 "Invalid" ;
VAL_ 1342 ISLA_SwIgnoreReq 0 "Allow All Switch Inputs (default)" 1 "-(SET) Switch Input Ignore" 2 "+(SET) Switch Input Ignore" 3 "-(SET) & +(SET) Switch Inputs Ignore" ;
VAL_ 1342 ISLA_SpdChgReq 0 "Default" 1 "Speed Change Request" 2 "Reserved" 3 "Reserved" ;
VAL_ 1342 ISLA_SpdWrn 0 "No Warning" 1 "Warning" ;
VAL_ 1342 ISLA_SymFlashMod 0 "No Flashing" 1 "Flashing Sign" 2 "Flashing - Arrow Symbol" 3 "Flashing + Arrow Symbol" 4 "Flashing Auto Symbol" 5 "Reserved" 6 "Reserved" 7 "Reserved" ;
VAL_ 1345 CF_Gway_DrvDrSw 0 "Close" 1 "Open" 3 "B-CAN signal Time-out" ;
VAL_ 1345 CF_Gway_DrvSeatBeltSw 0 "Unbelted" 1 "Belted" 3 "B-CAN signal Time-out" ;
VAL_ 1345 CF_Gway_TurnSigLh 0 "Off" 1 "On" 3 "B-CAN Time-out" ;
VAL_ 1345 CF_Gway_WiperIntT 0 "Step1(SLOW)" 1 "Step2" 2 "Step3" 3 "Step4" 4 "Step5(FAST)" ;
VAL_ 1345 CF_Gway_WiperIntSw 0 "Off" 1 "On" ;
VAL_ 1345 CF_Gway_WiperLowSw 0 "Off" 1 "On" ;
VAL_ 1345 CF_Gway_WiperHighSw 0 "Off" 1 "On" ;
VAL_ 1345 CF_Gway_WiperAutoSw 0 "Off" 1 "On" ;
VAL_ 1345 CF_Gway_RainSnsState 0 "OFF" 1 "Rain Detected" 2 "Low" 3 "High" 4 "Fault 1" 5 "Fault 2" 6 "Fault 3" 7 "Reserved" ;
VAL_ 1345 CF_Gway_HeadLampHigh 0 "Off" 1 "On" ;
VAL_ 1345 CF_Gway_HazardSw 0 "Off" 1 "On" 3 "B-CAN signal Time-out" ;
VAL_ 1345 CF_Gway_AstDrSw 0 "Close" 1 "Open" ;
VAL_ 1345 CF_Gway_TSigRHSw 0 "Off" 1 "On" ;
VAL_ 1345 CF_Gway_TSigLHSw 0 "Off" 1 "On" ;
VAL_ 1345 CF_Gway_HBAControlMode 0 "HLamp High Control Mode by BCM" 1 "HLamp High Control Mode by HBA" ;
VAL_ 1345 CF_Gway_InhibitRMT 0 "Gear_R Switch Off" 1 "Gear_R Switch On" 3 "B-CAN signal Time-out" ;
VAL_ 1345 CF_Gway_TurnSigRh 0 "Off" 1 "On" 3 "B-CAN Time-out" ;
VAL_ 1348 Navi_ISLW_SpdLimit 0 "None" 1 "1~253:1~253" 253 "1~253:1~253" 254 "Unlimited" 255 "Invalid" ;
VAL_ 1348 Navi_ISLW_Frwinfo 0 "None" 1 "Entrance" 2 "Exit" 3 "Branch" 4 "Restarea" 7 "Invalid" ;
VAL_ 1348 Navi_ISLW_SpdUnit 0 "None" 1 "KPH" 2 "MPH" 3 "Invalid" ;
VAL_ 1348 HU_AliveStatus 0 "Not Ready" 1 "On Mode" 2 "Head Unit Update Mode" 3 "Invalid" ;
VAL_ 1348 Navi_ISLW_LinkClass 0 "Unknown" 1 "Freeway" 2 "IC" 3 "JC" 4 "Restarea" 5 "Aterial/Country" 6 "RoundAbout" 7 "Invalid" ;
VAL_ 1348 Navi_ISLW_CountryCode 0 "Unknown" 1 "1~1022:ISO 3166-1 numeric values" 1022 "1~1022:ISO 3166-1 numeric values" 1023 "Invalid" ;
VAL_ 1348 NAVI_ISLWMapSource 0 "None" 1 "Embedded Map (HERE, HMNS)" 2 "Server Data (TOMTOM, MCP, TPEG)" 3 "Reserved" 4 "Reserved" 5 "Reserved" 6 "Reserved" 7 "Invalid" ;
VAL_ 1363 CF_Gway_RRDrSw 0 "Close" 1 "Open" ;
VAL_ 1363 CF_Gway_RLDrSw 0 "Close" 1 "Open" ;
VAL_ 1363 CF_Gway_WiperParkPosition 0 "else" 1 "Parking Position" ;
VAL_ 1382 ISLA_EUCntry1USMSta 0 "Default" 1 "1~254:Country 1 ~ 254" 254 "1~254:Country 1 ~ 254" 255 "Invalid" ;
VAL_ 1382 ISLA_EUCntry2USMSta 0 "Default" 1 "1~254:Country 1 ~ 254" 254 "1~254:Country 1 ~ 254" 255 "Invalid" ;
VAL_ 1382 ISLA_EUCntryVerTyp 0 "Default" 1 "Version 1 ~ 14" 2 "Version 1 ~ 14" 3 "Version 1 ~ 14" 4 "Version 1 ~ 14" 5 "Version 1 ~ 14" 6 "Version 1 ~ 14" 7 "Version 1 ~ 14" 8 "Version 1 ~ 14" 9 "Version 1 ~ 14" 10 "Version 1 ~ 14" 11 "Version 1 ~ 14" 12 "Version 1 ~ 14" 13 "Version 1 ~ 14" 14 "Version 1 ~ 14" 15 "Invalid" ;
VAL_ 1407 HU_Type 128 "Premium Navi 5th Gen(w/Navi)" 129 "Premium Navi 5th Gen(w/o Navi)" 130 "Premium Navi 6th Gen(w/ Navi)" 131 "Premium Navi 6th Gen(w/o Navi)" 16 "AVN(Tuner DVD KOR)" 17 "AVN(Tuner DVD EUR)" 18 "AVN(Tuner DVD China)" 19 "AVN(Tuner DVD Japan)" 20 "AVN(Tuner DVD EUR)" 21 "AVN(Tuner CDP KOR)" 22 "AVN(Tuner CDP EUR)" 23 "AVN(Tuner CDP China)" 24 "AVN(Tuner CDP Japan)" 25 "AVN(Tuner CDP EUR)" 32 "AVNT (Open)" 33 "AVNT (Not open)" 48 "Economic Audio" 64 "Standard Audio (3.0 below)" 65 "Standard Audio 4.0" 66 "STD Audio-3.0Below,No interwork" 67 "Audio 4.0 Value" 80 "AV(Tuner DVD KOR)" 81 "AV(Tuner DVD EUR)" 82 "AV(Tuner DVD China)" 83 "AV(Tuner DVD Japan)" 84 "AV(Tuner DVD EUR)" 85 "AV(Tuner CDP KOR)" 86 "AV(Tuner CDP EUR)" 87 "AV(Tuner CDP China)" 88 "AV(Tuner CDP Japan)" 89 "AV(Tuner CDP EUR)" 96 "AVN 4.0" 97 "Premium AVN2.0" 98 "EU AVN 2.0" 99 "Super Premium w Navi" 100 "Super Premium w_o Navi" 101 "Premium w Navi" 102 "Premium w_o Navi" 103 "Display Audio w_o Navi" 104 "Integrated AVN 1.0 Mobis" 105 "Gen5 Standard Nav Wide" 238 "India PIO w_o CLU interface" 239 "India PIO w_CLU interface" 112 "Compact AVN & Integrated AVN 1.0 LG" 250 "PIO AVN" 251 "China only OEM AV" 252 "China OPIO w_o CLU interface" 253 "China OPIO w_CLU interface" 254 "China OEM AVNT" 255 "Invalid" ;
VAL_ 1407 HU_OptionInfo 32768 "Invalid" ;
VAL_ 1470 HU_NaviStatus 0 "Booting" 1 "Normal Operation" 2 "No SD Card(Map)" 3 "Invalid" ;
VAL_ 1474 CF_Clu_AdasISLASetReq 0 "Default" 1 "Off" 2 "ISLW" 3 "ISLA" 4 "Reserved" 5 "Reserved" 6 "Reserved" 7 "Invalid" ;
VAL_ 1474 CF_Clu_ISLAOffsetSetReq 0 "Default" 1 "-10kph -5mph" 2 "-5kph -3mph" 3 "0" 4 "5kph 3mph" 5 "10kph 5mph" 6 "Reserved" 7 "Invalid" ;
VAL_ 2015 FRM_FORMAT 2 "Single frame and should analyze next two data of this message" ;
VAL_ 2015 SID 40 "Disable transmission of normal CAN messages. (Stop normal CAN communication)" 41 "Enable transmission of normal CAN messages. (Resume normal CAN communication)" ;
VAL_ 2015 REQ_RESPONSE 0 "Reserved" 1 "Response required" 2 "No response required" ;
